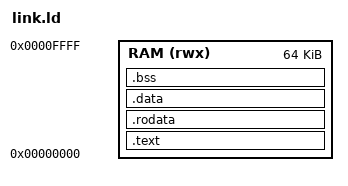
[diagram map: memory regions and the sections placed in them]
/* Flat 64 KiB: code and data from 0, stack grows down from the top. */
ENTRY(_start)
MEMORY { RAM (rwx) : ORIGIN = 0, LENGTH = 64K }
SECTIONS {
    .text : { KEEP(*(.text.start)) *(.text*) } > RAM
    .rodata : { *(.rodata*) *(.srodata*) } > RAM
    .data : { *(.data*) *(.sdata*) } > RAM
    .bss (NOLOAD) : { __bss_start = .; *(.bss*) *(.sbss*) *(COMMON) __bss_end = .; } > RAM
    __stack_top = ORIGIN(RAM) + LENGTH(RAM);
}
